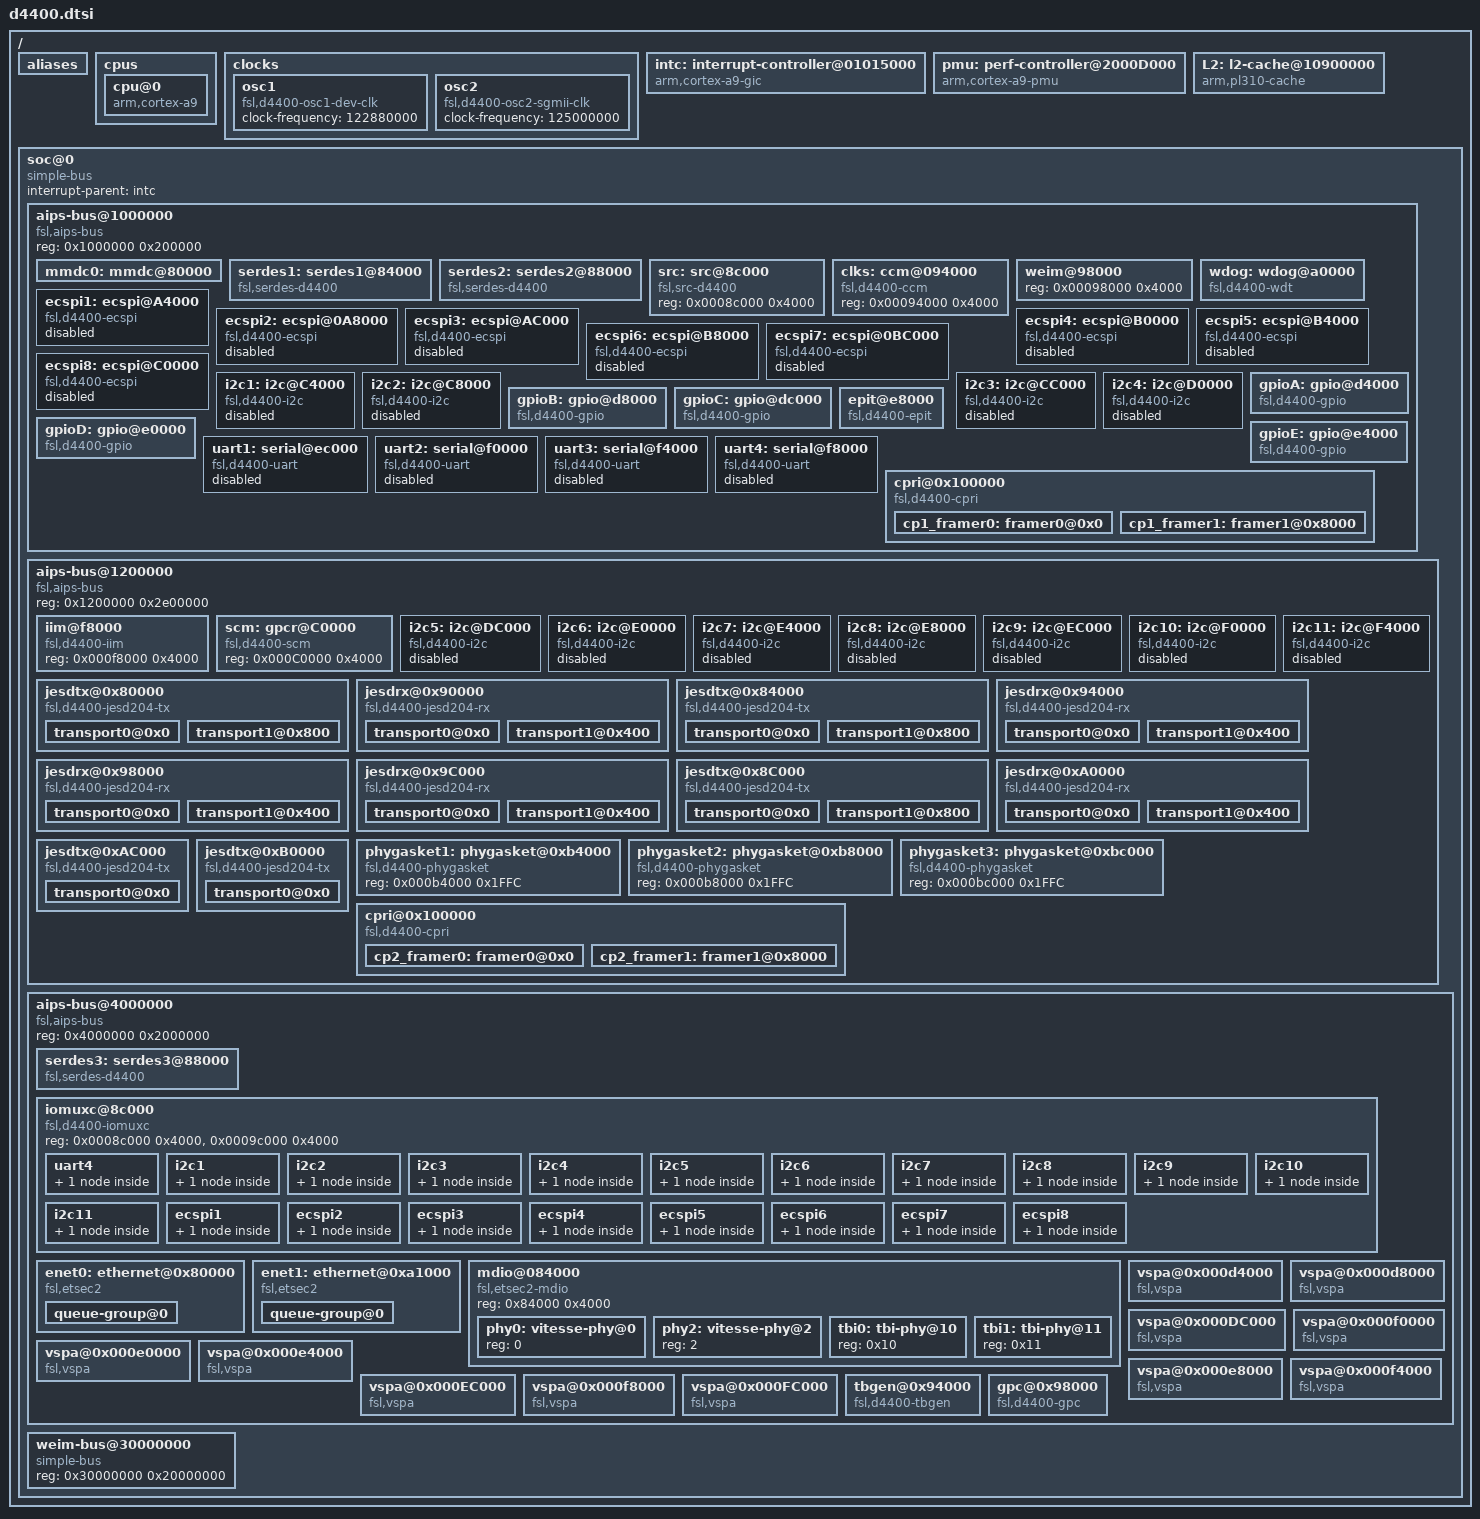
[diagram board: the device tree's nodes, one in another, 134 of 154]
/*
 * Copyright 2013 Freescale Semiconductor, Inc.
 * Copyright 2011 Linaro Ltd.
 *
 * The code contained herein is licensed under the GNU General Public
 * License. You may obtain a copy of the GNU General Public License
 * Version 2 or later at the following locations:
 *
 * http://www.opensource.org/licenses/gpl-license.html
 * http://www.gnu.org/copyleft/gpl.html
 */

/include/ "skeleton.dtsi"

/ {
        aliases {
                serial0 = &uart1;
                serial1 = &uart2;
                serial2 = &uart3;
                serial3 = &uart4;
                gpio0 = &gpioA;
                gpio1 = &gpioB;
                gpio2 = &gpioC;
                gpio3 = &gpioD;
                gpio4 = &gpioE;
		ethernet0 = &enet0;
		ethernet1 = &enet1;
		cpri0ethernet0 = &cp1_framer0;
		cpri0ethernet1 = &cp1_framer1;
		cpri1ethernet0 = &cp2_framer0;
		cpri1ethernet1 = &cp2_framer1;
        };

        cpus {
                #address-cells = <1>;
                #size-cells = <0>;

                cpu@0 {
                        compatible = "arm,cortex-a9";
                        reg = <0>;
                        next-level-cache = <&L2>;
                };
        };

        clocks {
                #address-cells = <1>;
                #size-cells = <0>;
                osc1 {
                        compatible = "fsl,d4400-osc1-dev-clk", "fixed-clock";
                        clock-frequency = <122880000>;
                };

                osc2 {
                        compatible = "fsl,d4400-osc2-sgmii-clk", "fixed-clock";
                        clock-frequency = <125000000>;
                };


        };

        intc: interrupt-controller@01015000 {
                compatible = "arm,cortex-a9-gic";
                #interrupt-cells = <3>;
                #address-cells = <1>;
                #size-cells = <1>;
                interrupt-controller;
                reg = <0x01015000 0x1000>, /* distributor address */
                      <0x01014100 0x100>;  /* CPU interface address */
        };

        pmu: perf-controller@2000D000 {
                compatible = "arm,cortex-a9-pmu";
                interrupts = <0 60 0x04>;
                reg = <0x2000D000 0x1000>;
        };

        L2: l2-cache@10900000 {
                compatible = "arm,pl310-cache";
                reg = <0x10900000 0x4000>;
                interrupts = <0 59 0x04>;
                cache-unified;
                cache-level = <2>;
        };

        soc@0 {
                #address-cells = <1>;
                #size-cells = <1>;
                compatible = "simple-bus";
                interrupt-parent = <&intc>;
                ranges = <0x0 0x0 0xFFFFFFFF>;

                aips-bus@1000000 { /* AIPS1 */
                        compatible = "fsl,aips-bus", "simple-bus";
                        #address-cells = <1>;
                        #size-cells = <1>;
                        reg = <0x1000000 0x200000>;
                        ranges = <0x0 0x1000000 0x200000>;

                        mmdc0: mmdc@80000 { /* MMDC0 */
                                reg = <0x00080000 0x4000>;
                                interrupts = <0 45 0x04>;
                        };

			serdes1: serdes1@84000 {
				#address-cells = <1>;
				#size-cells = <1>;
				#serdes-cells = <1>;
				compatible = "fsl,serdes-d4400";
				serdes-id = <1>;
				max-lane = <8>;
				reg = <0x00084000 0x4000>;
			};

			serdes2: serdes2@88000 {
				#address-cells = <1>;
				#size-cells = <1>;
				#serdes-cells = <1>;
				compatible = "fsl,serdes-d4400";
				serdes-id = <2>;
				max-lane = <8>;
				reg = <0x00088000 0x4000>;
			};

			src: src@8c000 {
				#address-cells = <1>;
				#size-cells = <1>;
				#src-cells = <1>;
				compatible = "fsl,src-d4400";
				reg = <0x0008c000 0x4000>;
			};

                        clks: ccm@094000 {
                                compatible = "fsl,d4400-ccm";
                                reg = <0x00094000 0x4000>;
                                #clock-cells = <1>;
                        };

                        weim@98000 {
                                reg = <0x00098000 0x4000>;
                        };

			wdog: wdog@a0000 {
				reg = <0x000a0000 0x4000>;
                                compatible = "fsl,d4400-wdt";
				interrupts = <0 47 0x04>;
				clocks = <&clks 31>;
			};

			ecspi1: ecspi@A4000 {
				#address-cells = <1>;
				#size-cells = <0>;
				compatible = "fsl,d4400-ecspi";
				reg = <0x000A4000 0x4000>;
				interrupts = <0 13 0x04>;
				clocks = <&clks 32>, <&clks 33>;
				clock-names = "ipg", "per";
				status = "disabled";
			};

			ecspi2: ecspi@0A8000 {
				#address-cells = <1>;
				#size-cells = <0>;
				compatible = "fsl,d4400-ecspi";
				reg = <0x000A8000 0x4000>;
				interrupts = <0 14 0x04>;
				clocks = <&clks 34>, <&clks 35>;
				clock-names = "ipg", "per";
				status = "disabled";
			};

			ecspi3: ecspi@AC000 {
				#address-cells = <1>;
				#size-cells = <0>;
				compatible = "fsl,d4400-ecspi";
				reg = <0x000AC000 0x4000>;
				interrupts = <0 15 0x04>;
				clocks = <&clks 36>, <&clks 37>;
				clock-names = "ipg", "per";
				status = "disabled";
			};

			ecspi4: ecspi@B0000 {
				#address-cells = <1>;
				#size-cells = <0>;
				compatible = "fsl,d4400-ecspi";
				reg = <0x000B0000 0x4000>;
				interrupts = <0 16 0x04>;
				clocks = <&clks 38>, <&clks 39>;
				clock-names = "ipg", "per";
				status = "disabled";
			};

			ecspi5: ecspi@B4000 {
				#address-cells = <1>;
				#size-cells = <0>;
				compatible = "fsl,d4400-ecspi";
				reg = <0x000B4000 0x4000>;
				interrupts = <0 17 0x04>;
				clocks = <&clks 40>, <&clks 41>;
				clock-names = "ipg", "per";
				status = "disabled";
			};

			ecspi6: ecspi@B8000 {
				#address-cells = <1>;
				#size-cells = <0>;
				compatible = "fsl,d4400-ecspi";
				reg = <0x000B8000 0x4000>;
				interrupts = <0 18 0x04>;
				clocks = <&clks 42>, <&clks 43>;
				clock-names = "ipg", "per";
				status = "disabled";
			};

			ecspi7: ecspi@0BC000 {
				#address-cells = <1>;
				#size-cells = <0>;
				compatible = "fsl,d4400-ecspi";
				reg = <0x000BC000 0x4000>;
				interrupts = <0 19 0x04>;
				clocks = <&clks 44>, <&clks 45>;
				clock-names = "ipg", "per";
				status = "disabled";
			};

			ecspi8: ecspi@C0000 {
				#address-cells = <1>;
				#size-cells = <0>;
				compatible = "fsl,d4400-ecspi";
				reg = <0x000C0000 0x4000>;
				interrupts = <0 20 0x04>;
				clocks = <&clks 46>, <&clks 47>;
				clock-names = "ipg", "per";
				status = "disabled";
			};

			i2c1: i2c@C4000 {
				#address-cells = <1>;
				#size-cells = <0>;
				compatible = "fsl,d4400-i2c";
				reg = <0x000C4000 0x4000>;
				interrupts = <0 48 0x04>;
				clocks = <&clks 65>;
				status = "disabled";
			};

			i2c2: i2c@C8000 {
				#address-cells = <1>;
				#size-cells = <0>;
				compatible = "fsl,d4400-i2c";
				reg = <0x000C8000 0x4000>;
				interrupts = <0 49 0x04>;
				clocks = <&clks 66>;
				status = "disabled";
			};

			i2c3: i2c@CC000 {
				#address-cells = <1>;
				#size-cells = <0>;
				compatible = "fsl,d4400-i2c";
				reg = <0x000CC000 0x4000>;
				interrupts = <0 50 0x04>;
				clocks = <&clks 67>;
				status = "disabled";
			};

			i2c4: i2c@D0000 {
				#address-cells = <1>;
				#size-cells = <0>;
				compatible = "fsl,d4400-i2c";
				reg = <0x000D0000 0x4000>;
				interrupts = <0 51 0x04>;
				clocks = <&clks 68>;
				status = "disabled";
			};

                        gpioA: gpio@d4000 {
                                compatible = "fsl,d4400-gpio";
                                reg = <0x000d4000 0x4000>;
                                interrupts = <0 159 0x04>;
                                gpio-controller;
                                #gpio-cells = <2>;
                                interrupt-controller;
                                #interrupt-cells = <2>;
                        };

                        gpioB: gpio@d8000 {
                                compatible = "fsl,d4400-gpio";
                                reg = <0x000d8000 0x4000>;
                                interrupts = <0 160 0x04>;
                                gpio-controller;
                                #gpio-cells = <2>;
                                interrupt-controller;
                                #interrupt-cells = <2>;
                        };

                        gpioC: gpio@dc000 {
                                compatible = "fsl,d4400-gpio";
                                reg = <0x000dc000 0x4000>;
                                interrupts = <0 161 0x04>;
                                gpio-controller;
                                #gpio-cells = <2>;
                                interrupt-controller;
                                #interrupt-cells = <2>;
                        };

                        gpioD: gpio@e0000 {
                                compatible = "fsl,d4400-gpio";
                                reg = <0x000e0000 0x4000>;
                                interrupts = <0 162 0x04>;
                                gpio-controller;
                                #gpio-cells = <2>;
                                interrupt-controller;
                                #interrupt-cells = <2>;
                        };

                        gpioE: gpio@e4000 {
                                compatible = "fsl,d4400-gpio";
                                reg = <0x000e4000 0x4000>;
                                interrupts = <0 163 0x04>;
                                gpio-controller;
                                #gpio-cells = <2>;
                                interrupt-controller;
                                #interrupt-cells = <2>;
                        };

                        epit@e8000 {
				compatible = "fsl,d4400-epit";
                                reg = <0x000e8000 0x4000>;
                                interrupts = <0 22 0x04>;
                        };

                        uart1: serial@ec000 {
                                 compatible = "fsl,d4400-uart";
                                 reg = <0x000ec000 0x4000>;
                                 interrupts = <0 0 0x04>;
                                 clocks = <&clks 57>, <&clks 18>;
                                 clock-names = "ipg", "per";
                                 status = "disabled";
                        };

                        uart2: serial@f0000 {
                                 compatible = "fsl,d4400-uart";
                                 reg = <0x000f0000 0x4000>;
                                 interrupts = <0 1 0x04>;
                                 clocks = <&clks 59>, <&clks 20>;
                                 clock-names = "ipg", "per";
                                 status = "disabled";
                        };

                        uart3: serial@f4000 {
                                 compatible = "fsl,d4400-uart";
                                 reg = <0x000f4000 0x4000>;
                                 interrupts = <0 2 0x04>;
                                 clocks = <&clks 61>, <&clks 22>;
                                 clock-names = "ipg", "per";
                                 status = "disabled";
                        };

                        uart4: serial@f8000 {
                                 compatible = "fsl,d4400-uart";
                                 reg = <0x000f8000 0x4000>;
                                 interrupts = <0 3 0x04>;
                                 clocks = <&clks 63>, <&clks 24>;
                                 clock-names = "ipg", "per";
                                 status = "disabled";
                        };
			cpri@0x100000 {
				#address-cells = <1>;
				#size-cells = <1>;
				compatible = "fsl,d4400-cpri";
				id = <1>;
				ranges = <0x0 0x100000 0x10000>;
				reg = <0x00107E00 0x400>;
				status = "okay";
				interrupts = <0 67 0x4>,
					<0 68 0x4>,
					<0 69 0x4>,
					<0 70 0x4>,
					<0 79 0x4>;

			cp1_framer0: framer0@0x0 {
				reg = <0x0 0x8000>;
				framer-id = <1>;
				max-axcs = <24>;
				memblk-rx = <0x83000000 0x1800 0x83801800 0x1800>;
				memblk-tx = <0x83000000 0x1800 0x83801800 0x1800>;
				local-mac-address = [ 00 00 AB CD 21 AB ];
				interrupts = <0 71 0x04>,
					 <0 73 0x04>,
					 <0 75 0x04>,
					 <0 77 0x04>;
				sfp-handle = <&cpriphy0>;
				serdes-handle = <&serdes3 2>;
			};

			cp1_framer1: framer1@0x8000 {
				reg = <0x8000 0x8000>;
				framer-id = <2>;
				max-axcs = <24>;
				memblk-rx = <0x84000000 0x1800 0x84801800 0x1800>;
				memblk-tx = <0x84000000 0x1800 0x84801800 0x1800>;
				local-mac-address = [ 00 00 AB CD 21 CD ];
				interrupts = <0 72 0x4>,
					 <0 74 0x4>,
					 <0 76 0x4>,
					 <0 78 0x4>;
				sfp-handle = <&cpriphy1>;
				serdes-handle = <&serdes3 3>;
				};
			};



                };

                aips-bus@1200000 { /* AIPS2 */
                        compatible = "fsl,aips-bus", "simple-bus";
                        #address-cells = <1>;
                        #size-cells = <1>;
                        reg = <0x1200000 0x2e00000>;
                        ranges = <0x0 0x1200000 0x2e00000>;
			iim@f8000 {
				compatible = "fsl,d4400-iim";
				reg = <0x000f8000 0x4000>;
			};
			scm: gpcr@C0000 {
                                 compatible = "fsl,d4400-scm";
                                 reg = <0x000C0000 0x4000>;
			};

			i2c5: i2c@DC000 {
				#address-cells = <1>;
				#size-cells = <0>;
				compatible = "fsl,d4400-i2c";
				reg = <0x000DC000 0x4000>;
				interrupts = <0 52 0x04>;
				clocks = <&clks 69>;
				status = "disabled";
			};

			i2c6: i2c@E0000 {
				#address-cells = <1>;
				#size-cells = <0>;
				compatible = "fsl,d4400-i2c";
				reg = <0x000E0000 0x4000>;
				interrupts = <0 53 0x04>;
				clocks = <&clks 70>;
				status = "disabled";
			};

			i2c7: i2c@E4000 {
				#address-cells = <1>;
				#size-cells = <0>;
				compatible = "fsl,d4400-i2c";
				reg = <0x000E4000 0x4000>;
				interrupts = <0 54 0x04>;
				clocks = <&clks 71>;
				status = "disabled";
			};

			i2c8: i2c@E8000 {
				#address-cells = <1>;
				#size-cells = <0>;
				compatible = "fsl,d4400-i2c";
				reg = <0x000E8000 0x4000>;
				interrupts = <0 55 0x04>;
				clocks = <&clks 72>;
				status = "disabled";
			};

			i2c9: i2c@EC000 {
				#address-cells = <1>;
				#size-cells = <0>;
				compatible = "fsl,d4400-i2c";
				reg = <0x000EC000 0x4000>;
				interrupts = <0 56 0x04>;
				clocks = <&clks 73>;
				status = "disabled";
			};

			i2c10: i2c@F0000 {
				#address-cells = <1>;
				#size-cells = <0>;
				compatible = "fsl,d4400-i2c";
				reg = <0x000F0000 0x4000>;
				interrupts = <0 57 0x04>;
				clocks = <&clks 74>;
				status = "disabled";
			};

			i2c11: i2c@F4000 {
				#address-cells = <1>;
				#size-cells = <0>;
				compatible = "fsl,d4400-i2c";
				reg = <0x000F4000 0x4000>;
				interrupts = <0 58 0x04>;
				clocks = <&clks 75>;
				status = "disabled";
			};

			jesdtx@0x80000{
				#address-cells = <1>;
				#size-cells = <1>;
				compatible = "fsl,d4400-jesd204-tx";
				ranges = <0x0 0x80000 0x4000>;
				reg = <0x00080000 0x4000>;
				lanes = <2>;

				transport0@0x0{
					reg = <0x0000000 0x7FC>;
					transport-type = <0>;
					transport-id = <0>;
					timer-id = <0>;
					pll-id = <0>;
					phy-gasket = <&phygasket1>;
					max-lanes = <2>;
					serdes-lanes = <&serdes1 0>,
						<&serdes1 1>;
					interrupts = <0 119 0x4>;
				};

				transport1@0x800{
					reg = <0x00000800 0x7FC>;
					transport-type = <0>;
					transport-id = <1>;
					timer-id = <1>;
					pll-id = <0>;
					phy-gasket = <&phygasket1>;
					max-lanes = <1>;
					serdes-lanes = <&serdes1 1>;
					interrupts = <0 120 0x4>;
				};
			};

			jesdrx@0x90000{
				#address-cells = <1>;
				#size-cells = <1>;
				compatible = "fsl,d4400-jesd204-rx";
				ranges = <0x0 0x90000 0x4000>;
				reg = <0x00090000 0x4000>;
				lanes = <2>;

				transport0@0x0{
					reg = <0x00000000 0x3FF>;
					transport-type = <2>;
					transport-id = <0>;
					timer-id = <0>;
					pll-id = <0>;
					phy-gasket = <&phygasket1>;
					max-lanes = <2>;
					serdes-lanes = <&serdes1 0>,
						<&serdes1 1>;
					interrupts = <0 106 0x4>;
				};

				transport1@0x400{
					reg = <0x00000400 0x3FF>;
					transport-type = <2>;
					transport-id = <1>;
					timer-id = <1>;
					pll-id = <0>;
					phy-gasket = <&phygasket1>;
					max-lanes = <1>;
					serdes-lanes = <&serdes1 1>;
					interrupts = <0 107 0x4>;
				};
			};

			jesdtx@0x84000{
				#address-cells = <1>;
				#size-cells = <1>;
				compatible = "fsl,d4400-jesd204-tx";
				ranges = <0x0 0x84000 0x4000>;
				reg = <0x00084000 0x4000>;
				lanes = <2>;

				transport0@0x0{
					reg = <0x0000000 0x7FC>;
					transport-type = <0>;
					transport-id = <2>;
					timer-id = <2>;
					pll-id = <0>;
					phy-gasket = <&phygasket1>;
					max-lanes = <2>;
					serdes-lanes = <&serdes1 2>,
						<&serdes1 3>;
					interrupts = <0 121 0x4>;
				};

				transport1@0x800{
					reg = <0x00000800 0x7FC>;
					transport-type = <0>;
					transport-id = <3>;
					timer-id = <3>;
					pll-id = <0>;
					phy-gasket = <&phygasket1>;
					max-lanes = <1>;
					serdes-lanes = <&serdes1 3>;
					interrupts = <0 122 0x4>;
				};
			};

			jesdrx@0x94000{
				#address-cells = <1>;
				#size-cells = <1>;
				compatible = "fsl,d4400-jesd204-rx";
				ranges = <0x0 0x94000 0x4000>;
				reg = <0x00094000 0x4000>;
				lanes = <2>;

				transport0@0x0{
					reg = <0x00000000 0x3FF>;
					transport-type = <1>;
					transport-id = <2>;
					timer-id = <0>;
					pll-id = <0>;
					phy-gasket = <&phygasket1>;
					max-lanes = <2>;
					serdes-lanes = <&serdes1 2>,
						<&serdes1 3>;
					interrupts = <0 108 0x4>;
				};

				transport1@0x400{
					reg = <0x00000400 0x3FF>;
					transport-type = <1>;
					transport-id = <3>;
					timer-id = <1>;
					pll-id = <0>;
					phy-gasket = <&phygasket1>;
					max-lanes = <1>;
					serdes-lanes = <&serdes1 3>;
					interrupts = <0 109 0x4>;
				};
			};

			jesdrx@0x98000{
				#address-cells = <1>;
				#size-cells = <1>;
				compatible = "fsl,d4400-jesd204-rx";
				ranges = <0x0 0x98000 0x4000>;
				reg = <0x00098000 0x4000>;
				lanes = <2>;

				transport0@0x0{
					reg = <0x00000000 0x3FF>;
					transport-type = <2>;
					transport-id = <4>;
					timer-id = <2>;
					pll-id = <0>;
					phy-gasket = <&phygasket1>;
					max-lanes = <2>;
					serdes-lanes = <&serdes1 4>,
						<&serdes1 5>;
					interrupts = <0 110 0x4>;
				};

				transport1@0x400{
					reg = <0x00000400 0x3FF>;
					transport-type = <2>;
					transport-id = <5>;
					timer-id = <3>;
					pll-id = <0>;
					phy-gasket = <&phygasket1>;
					max-lanes = <1>;
					serdes-lanes = <&serdes1 5>;
					interrupts = <0 111 0x4>;
				};
			};

			jesdrx@0x9C000{
				#address-cells = <1>;
				#size-cells = <1>;
				compatible = "fsl,d4400-jesd204-rx";
				ranges = <0x0 0x9C000 0x4000>;
				reg = <0x0009C000 0x4000>;
				lanes = <2>;

				transport0@0x0{
					reg = <0x00000000 0x3FF>;
					transport-type = <1>;
					transport-id = <6>;
					timer-id = <2>;
					pll-id = <0>;
					phy-gasket = <&phygasket1>;
					max-lanes = <2>;
					serdes-lanes = <&serdes1 6>,
						<&serdes1 7>;
					interrupts = <0 112 0x4>;
				};

				transport1@0x400{
					reg = <0x00000400 0x3FF>;
					transport-type = <1>;
					transport-id = <7>;
					timer-id = <3>;
					pll-id = <0>;
					phy-gasket = <&phygasket1>;
					max-lanes = <1>;
					serdes-lanes = <&serdes1 7>;
					interrupts = <0 113 0x4>;
				};
			};

			jesdtx@0x8C000{
				#address-cells = <1>;
				#size-cells = <1>;
				compatible = "fsl,d4400-jesd204-tx";
				ranges = <0x0 0x8C000 0x4000>;
				reg = <0x0008C000 0x4000>;
				lanes = <2>;

				transport0@0x0{
					reg = <0x0000000 0x7FC>;
					transport-type = <0>;
					transport-id = <6>;
					timer-id = <6>;
					pll-id = <0>;
					phy-gasket = <&phygasket1>;
					max-lanes = <2>;
					serdes-lanes = <&serdes1 6>,
						<&serdes1 7>;
					interrupts = <0 125 0x4>;
				};

				transport1@0x800{
					reg = <0x00000800 0x7FC>;
					transport-type = <0>;
					transport-id = <7>;
					timer-id = <7>;
					pll-id = <0>;
					phy-gasket = <&phygasket1>;
					max-lanes = <1>;
					serdes-lanes = <&serdes1 7>;
					interrupts = <0 126 0x4>;
				};
			};

			jesdrx@0xA0000{
				#address-cells = <1>;
				#size-cells = <1>;
				compatible = "fsl,d4400-jesd204-rx";
				ranges = <0x0 0xA0000 0x4000>;
				reg = <0x000A0000 0x4000>;
				lanes = <2>;

				transport0@0x0{
					reg = <0x00000000 0x3FF>;
					transport-type = <1>;
					transport-id = <8>;
					timer-id = <8>;
					pll-id = <1>;
					phy-gasket = <&phygasket2>;
					max-lanes = <2>;
					serdes-lanes = <&serdes2 2>,
						<&serdes2 3>;
					interrupts = <0 114 0x4>;
				};

				transport1@0x400{
					reg = <0x00000400 0x3FF>;
					transport-type = <1>;
					transport-id = <9>;
					timer-id = <9>;
					pll-id = <1>;
					phy-gasket = <&phygasket2>;
					max-lanes = <1>;
					serdes-lanes = <&serdes2 3>;
					interrupts = <0 115 0x4>;
				};
			};

			jesdtx@0xAC000{
				#address-cells = <1>;
				#size-cells = <1>;
				compatible = "fsl,d4400-jesd204-tx";
				ranges = <0x0 0xAC000 0x4000>;
				reg = <0x000AC000 0x4000>;
				lanes = <2>;

				transport0@0x0{
					reg = <0x0000000 0x7FC>;
					transport-type = <0>;
					transport-id = <8>;
					timer-id = <8>;
					pll-id = <2>;
					phy-gasket = <&phygasket3>;
					max-lanes = <2>;
					serdes-lanes = <&serdes3 4>,
						<&serdes3 5>;
					interrupts = <0 127 0x4>;
				};
			};

			jesdtx@0xB0000{
				#address-cells = <1>;
				#size-cells = <1>;
				compatible = "fsl,d4400-jesd204-tx";
				ranges = <0x0 0xB0000 0x4000>;
				reg = <0x000B0000 0x4000>;
				lanes = <2>;

				transport0@0x0{
					reg = <0x0000000 0x7FC>;
					transport-type = <0>;
					transport-id = <9>;
					timer-id = <9>;
					pll-id = <2>;
					phy-gasket = <&phygasket3>;
					max-lanes = <2>;
					serdes-lanes = <&serdes3 6>,
						<&serdes3 7>;
					interrupts = <0 128 0x4>;
				};
			};

			phygasket1: phygasket@0xb4000 {
				#address-cells = <1>;
				#size-cells = <1>;
				compatible = "fsl,d4400-phygasket";
				reg = <0x000b4000 0x1FFC>;
			};

			phygasket2: phygasket@0xb8000 {
				#address-cells = <1>;
				#size-cells = <1>;
				compatible = "fsl,d4400-phygasket";
				reg = <0x000b8000 0x1FFC>;
			};

			phygasket3: phygasket@0xbc000 {
				#address-cells = <1>;
				#size-cells = <1>;
				compatible = "fsl,d4400-phygasket";
				reg = <0x000bc000 0x1FFC>;
			};

			cpri@0x100000 {
                                #address-cells = <1>;
                                #size-cells = <1>;
                                compatible = "fsl,d4400-cpri";
                                id = <2>;
                                ranges = <0x0 0x100000 0x10000>;
                                reg = <0x00107E00 0x400>;
                                status = "okay";
                                interrupts = <0 80 0x4>,
                                        <0 81 0x4>,
                                        <0 82 0x4>,
                                        <0 83 0x4>,
                                        <0 92 0x4>;

                        cp2_framer0: framer0@0x0 {
                                reg = <0x0 0x8000>;
                                framer-id = <1>;
                                max-axcs = <24>;
                                memblk-rx = <0x85000000 0x1800 0x85801800 0x1800>;
                                memblk-tx = <0x85000000 0x1800 0x85801800 0x1800>;
                                local-mac-address = [ 00 00 AB CD 21 EF ];
                                interrupts = <0 84 0x04>,
                                         <0 86 0x04>,
                                         <0 88 0x04>,
                                         <0 90 0x04>;
                                sfp-handle = <&cpriphy2>;
                                serdes-handle = <&serdes3 4>;
                        };

                        cp2_framer1: framer1@0x8000 {
                                reg = <0x8000 0x8000>;
                                framer-id = <2>;
                                max-axcs = <24>;
                                memblk-rx = <0x86000000 0x1800 0x86801800 0x1800>;
                                memblk-tx = <0x86000000 0x1800 0x86801800 0x1800>;
                                local-mac-address = [ 00 00 AB CD 22 AB ];
                                interrupts = <0 85 0x4>,
                                         <0 87 0x4>,
                                         <0 89 0x4>,
                                         <0 91 0x4>;
                                sfp-handle = <&cpriphy3>;
                                serdes-handle = <&serdes3 5>;
                                };
                        };


                };

                aips-bus@4000000 { /* AIPS3 */
                        compatible = "fsl,aips-bus", "simple-bus";
                        #address-cells = <1>;
                        #size-cells = <1>;
                        reg = <0x4000000 0x2000000>;
                        ranges = <0x0 0x4000000 0x2000000>;

			serdes3: serdes3@88000 {
				#address-cells = <1>;
				#size-cells = <1>;
				#serdes-cells = <1>;
				compatible = "fsl,serdes-d4400";
				serdes-id = <3>;
				max-lane = <8>;
				reg = <0x00088000 0x4000>;
			};

                        iomuxc@8c000 {
                                compatible = "fsl,d4400-iomuxc";
                                reg = <0x0008c000 0x4000>, < 0x0009c000 0x4000>;
				reg-names = "iomuxc-ddr", "iomuxc-main";
                                uart4 {
                                        pinctrl_uart4_1: uart4grp-1 {
                                                fsl,pins = <
                                                        350 0x80000000    /* D4400_PAD_UART4_TXD_UART_4_TXD */
                                                        356 0x80000000    /* D4400_PAD_UART4_RXD_UART_4_RXD */
                                                >;
                                        };
                                };

				i2c1 {
					pinctrl_i2c1_1: i2c1grp-1 {
						fsl,pins = <
							362 0x80000000	/* D4400_PAD_I2C1_SDA_I2C_1_SDA */
							367 0x80000000	/* D4400_PAD_I2C1_SCL_I2C_1_SCL */
						>;
					};
				};

				i2c2 {
					pinctrl_i2c2_1: i2c2grp-1 {
						fsl,pins = <
							372 0x80000000	/* D4400_PAD_I2C2_SDA_I2C_2_SDA */
							377 0x80000000	/* D4400_PAD_I2C2_SCL_I2C_2_SCL */
						>;
					};
				};

				i2c3 {
					pinctrl_i2c3_1: i2c3grp-1 {
						fsl,pins = <
							382 0x80000000	/* D4400_PAD_I2C3_SDA_I2C_3_SDA */
							387 0x80000000	/* D4400_PAD_I2C3_SCL_I2C_3_SCL */
						>;
					};
				};

				i2c4 {
					pinctrl_i2c4_1: i2c4grp-1 {
						fsl,pins = <
							352 0x80000000	/* D4400_PAD_UART4_TXD_I2C_4_SDA */
							358 0x80000000	/* D4400_PAD_UART4_RXD_I2C_4_SCL */
						>;
					};
				};

				i2c5 {
					pinctrl_i2c5_1: i2c5grp-1 {
						fsl,pins = <
							392 0x80000000	/* D4400_PAD_I2C5_SDA_I2C_5_SDA */
							397 0x80000000	/* D4400_PAD_I2C5_SCL_I2C_5_SCL */
						>;
					};
				};

				i2c6 {
					pinctrl_i2c6_1: i2c6grp-1 {
						fsl,pins = <
							402 0x80000000	/* D4400_PAD_I2C6_SDA_I2C_6_SDA */
							407 0x80000000	/* D4400_PAD_I2C6_SCL_I2C_6_SCL */
						>;
					};
				};

				i2c7 {
					pinctrl_i2c7_1: i2c7grp-1 {
						fsl,pins = <
							412 0x80000000	/* D4400_PAD_I2C7_SDA_I2C_7_SDA */
							417 0x80000000	/* D4400_PAD_I2C7_SCL_I2C_7_SCL */
						>;
					};
				};

				i2c8 {
					pinctrl_i2c8_1: i2c8grp-1 {
						fsl,pins = <
							422 0x80000000	/* D4400_PAD_I2C8_SDA_I2C_8_SDA */
							430 0x80000000	/* D4400_PAD_I2C8_SCL_I2C_8_SCL */
						>;
					};
				};

				i2c9 {
					pinctrl_i2c9_1: i2c9grp-1 {
						fsl,pins = <
							438 0x80000000	/* D4400_PAD_I2C9_SDA_I2C_9_SDA */
							446 0x80000000	/* D4400_PAD_I2C9_SCL_I2C_9_SCL */
						>;
					};
				};

				i2c10 {
					pinctrl_i2c10_1: i2c10grp-1 {
						fsl,pins = <
							454 0x80000000	/* D4400_PAD_I2C10_SDA_I2C_10_SDA */
							462 0x80000000	/* D4400_PAD_I2C10_SCL_I2C_10_SCL */
						>;
					};
				};

				i2c11 {
					pinctrl_i2c11_1: i2c11grp-1 {
						fsl,pins = <
							470 0x80000000	/* D4400_PAD_I2C11_SDA_I2C_11_SDA */
							478 0x80000000	/* D4400_PAD_I2C11_SCL_I2C_11_SCL */
						>;
					};
				};

				ecspi1 {
					pinctrl_ecspi1_1: ecspi1grp-1 {
						fsl,pins = <
							182 0x80000000	/* D4400_PAD_SPI1_MOSI_ECSPI_1_MOSI */
							186 0x80000000	/* D4400_PAD_SPI1_MISO_ECSPI_1_MISO */
							189 0x80000000	/* D4400_PAD_SPI1_CLK_ECSPI_1_CLK */
							192 0x80000000	/* D4400_PAD_SPI1_SS0_ECSPI_1_SS_0 */
							195 0x80000000	/* D4400_PAD_SPI1_SS1_ECSPI_1_SS_1 */
							841 0x80000000  /* D4400_PAD_GPIOC0_ECSPI1_SS2 */
						>;
					};
				};

				ecspi2 {
					pinctrl_ecspi2_1: ecspi2grp-1 {
						fsl,pins = <
							198 0x80000000	/* D4400_PAD_SPI2_MOSI_ECSPI_2_MOSI */
							202 0x80000000	/* D4400_PAD_SPI2_MISO_ECSPI_2_MISO */
							205 0x80000000	/* D4400_PAD_SPI2_CLK_ECSPI_2_CLK */
							208 0x80000000	/* D4400_PAD_SPI2_SS0_ECSPI_2_SS_0 */
							211 0x80000000	/* D4400_PAD_SPI2_SS1_ECSPI_2_SS_1 */
						>;
					};
				};

				ecspi3 {
					pinctrl_ecspi3_1: ecspi3grp-1 {
						fsl,pins = <
							214 0x80000000	/* D4400_PAD_SPI3_MOSI_ECSPI_3_MOSI */
							218 0x80000000	/* D4400_PAD_SPI3_MISO_ECSPI_3_MISO */
							221 0x80000000	/* D4400_PAD_SPI3_CLK_ECSPI_3_CLK */
							224 0x80000000	/* D4400_PAD_SPI3_SS0_ECSPI_3_SS_0 */
							227 0x80000000	/* D4400_PAD_SPI3_SS1_ECSPI_3_SS_1 */
							873 0x80000000  /* D4400_PAD_GPIOC4_ECSPI3_SS2 */
						>;
					};
				};

				ecspi4 {
					pinctrl_ecspi4_1: ecspi4grp-1 {
						fsl,pins = <
							230 0x80000000	/* D4400_PAD_SPI4_MOSI_ECSPI_4_MOSI */
							234 0x80000000	/* D4400_PAD_SPI4_MISO_ECSPI_4_MISO */
							237 0x80000000	/* D4400_PAD_SPI4_CLK_ECSPI_4_CLK */
							240 0x80000000	/* D4400_PAD_SPI4_SS0_ECSPI_4_SS_0 */
							243 0x80000000	/* D4400_PAD_SPI4_SS1_ECSPI_4_SS_1 */
						>;
					};
				};

				ecspi5 {
					pinctrl_ecspi5_1: ecspi5grp-1 {
						fsl,pins = <
							246 0x80000000	/* D4400_PAD_SPI5_MOSI_ECSPI_5_MOSI */
							250 0x80000000	/* D4400_PAD_SPI5_MISO_ECSPI_5_MISO */
							253 0x80000000	/* D4400_PAD_SPI5_CLK_ECSPI_5_CLK */
							256 0x80000000	/* D4400_PAD_SPI5_SS0_ECSPI_5_SS_0 */
							259 0x80000000	/* D4400_PAD_SPI5_SS1_ECSPI_5_SS_1 */
						>;
					};
				};

				ecspi6 {
					pinctrl_ecspi6_1: ecspi6grp-1 {
						fsl,pins = <
							262 0x80000000	/* D4400_PAD_SPI6_MOSI_ECSPI_6_MOSI */
							267 0x80000000	/* D4400_PAD_SPI6_MISO_ECSPI_6_MISO */
							271 0x80000000	/* D4400_PAD_SPI6_CLK_ECSPI_6_CLK */
							275 0x80000000	/* D4400_PAD_SPI6_SS0_ECSPI_6_SS_0 */
							279 0x80000000	/* D4400_PAD_SPI6_SS1_ECSPI_6_SS_1 */
						>;
					};
				};

				ecspi7 {
					pinctrl_ecspi7_1: ecspi7grp-1 {
						fsl,pins = <
							282 0x80000000	/* D4400_PAD_SPI7_MOSI_ECSPI_7_MOSI */
							287 0x80000000	/* D4400_PAD_SPI7_MISO_ECSPI_7_MISO */
							291 0x80000000	/* D4400_PAD_SPI7_CLK_ECSPI_7_CLK */
							295 0x80000000	/* D4400_PAD_SPI7_SS0_ECSPI_7_SS_0 */
							299 0x80000000	/* D4400_PAD_SPI7_SS1_ECSPI_7_SS_1 */
						>;
					};
				};

				ecspi8 {
					pinctrl_ecspi8_1: ecspi8grp-1 {
						fsl,pins = <
							302 0x80000000	/* D4400_PAD_SPI8_MOSI_ECSPI_8_MOSI */
							307 0x80000000	/* D4400_PAD_SPI8_MISO_ECSPI_8_MISO */
							311 0x80000000	/* D4400_PAD_SPI8_CLK_ECSPI_8_CLK */
							316 0x80000000	/* D4400_PAD_SPI8_SS0_ECSPI_8_SS_0 */
							321 0x80000000	/* D4400_PAD_SPI8_SS1_ECSPI_8_SS_1 */
						>;
					};
				};

                        };

			enet0: ethernet@0x80000 {
				#address-cells = <1>;
				#size-cells = <1>;
				device_type = "network";
				model = "eTSEC";
				compatible = "fsl,etsec2";
				fsl,num_rx_queues = <0x08>;
				fsl,num_tx_queues = <0x08>;
				fsl,errata = <0x00000004>;
				local-mac-address = [ 00 00 ab cd 22 ef ];
				phy-handle = <&phy0>;
				tbi-handle = <&tbi0>;
				phy-connection-type = "sgmii";
				reg = <0x80000 0x1000>;
				ranges;
				status = "okay";

				queue-group@0 {
					#address-cells = <1>;
					#size-cells = <1>;
					reg-names = "queue-group0";
					reg = <0x80000 0x1000>;
					fsl,rx-bit-map = <0xFF>;
					fsl,tx-bit-map = <0xFF>;
					interrupts = <0 184 0x04>,
						     <0 183 0x04>,
						     <0 185 0x04>;
				};
			};

			enet1: ethernet@0xa1000 {
				#address-cells = <1>;
				#size-cells = <1>;
				device_type = "network";
				model = "eTSEC";
				compatible = "fsl,etsec2";
				fsl,num_rx_queues = <0x08>;
				fsl,num_tx_queues = <0x08>;
				fsl,errata = <0x00000004>;
				local-mac-address = [ 00 00 ab cd 23 ef ];
				phy-handle = <&phy2>;
				tbi-handle = <&tbi1>;
				phy-connection-type = "sgmii";
				reg = <0xa1000 0x1000>;
				ranges;
				status = "okay";

				queue-group@0 {
					#address-cells = <1>;
					#size-cells = <1>;
					reg-names = "queue-group0";
					reg = <0xa1000 0x1000>;
					fsl,rx-bit-map = <0xFF>;
					fsl,tx-bit-map = <0xFF>;
					interrupts = <0 191 0x04>,
						     <0 190 0x04>,
						     <0 192 0x04>;
				};
			};

			mdio@084000 {
				#address-cells = <1>;
				#size-cells = <0>;
				compatible = "fsl,etsec2-mdio";
				reg = <0x84000 0x4000>;
				status = "okay";

				phy0: vitesse-phy@0 {
					reg = <0>;
					device_type = "ethernet-phy";
				};

				phy2: vitesse-phy@2 {
					reg = <2>;
					device_type = "ethernet-phy";
				};

				tbi0: tbi-phy@10 {
					device_type = "tbi-phy";
					reg = <0x10>;
				};

				tbi1: tbi-phy@11 {
					device_type = "tbi-phy";
					reg = <0x11>;
				};
			};

			vspa@0x000d4000 {
				compatible = "fsl,vspa";
				reg = <0x000d4000 0x800>;
				dbgregstart = <0x20025000>;
				dbgreglen = <0x1000>;
				vspadev-id  = <11>;
				interrupts = <0 213 0x4>;
				status = "okay";
			};
			vspa@0x000d8000 {
				compatible = "fsl,vspa";
				reg = <0x000d8000 0x800>;
				dbgregstart = <0x20024000>;
				dbgreglen = <0x1000>;
				vspadev-id  = <10>;
				interrupts = <0 214 0x4>;
				status = "okay";
			};
			vspa@0x000DC000 {
				compatible = "fsl,vspa";
				reg = <0x000DC000 0x800>;
				dbgregstart = <0x20023000>;
				dbgreglen = <0x1000>;
				vspadev-id  = <9>;
				interrupts = <0 215 0x4>;
				status = "okay";
			};
			vspa@0x000e0000 {
				compatible = "fsl,vspa";
				reg = <0x000e0000 0x800>;
				dbgregstart = <0x20022000>;
				dbgreglen = <0x1000>;
				vspadev-id  = <8>;
				interrupts = <0 216 0x4>;
				status = "okay";
			};
			vspa@0x000e4000 {
				compatible = "fsl,vspa";
				reg = <0x000e4000 0x800>;
				dbgregstart = <0x20028000>;
				dbgreglen = <0x1000>;
				vspadev-id  = <7>;
				interrupts = <0 217 0x4>;
				status = "okay";
			};
			vspa@0x000e8000 {
				compatible = "fsl,vspa";
				reg = <0x000e8000 0x800>;
				dbgregstart = <0x20027000>;
				dbgreglen = <0x1000>;
				vspadev-id  = <6>;
				interrupts = <0 218 0x4>;
				status = "okay";
			};
			vspa@0x000EC000 {
				compatible = "fsl,vspa";
				reg = <0x000EC000 0x800>;
				dbgregstart = <0x20026000>;
				dbgreglen = <0x1000>;
				vspadev-id  = <5>;
				interrupts = <0 219 0x4>;
				status = "okay";
			};
			vspa@0x000f0000 {
				compatible = "fsl,vspa";
				reg = <0x000f0000 0x800>;
				dbgregstart = <0x20021000>;
				dbgreglen = <0x1000>;
				vspadev-id  = <4>;
				interrupts = <0 220 0x4>;
				status = "okay";
			};
			vspa@0x000f4000 {
				compatible = "fsl,vspa";
				reg = <0x000f4000 0x800>;
				dbgregstart = <0x20020000>;
				dbgreglen = <0x1000>;
				vspadev-id  = <3>;
				interrupts = <0 221 0x4>;
				status = "okay";
			};
			vspa@0x000f8000 {
				compatible = "fsl,vspa";
				reg = <0x000f8000 0x800>;
				dbgregstart = <0x2001F000>;
				dbgreglen = <0x1000>;
				vspadev-id  = <2>;
				interrupts = <0 222 0x4>;
				status = "okay";
			};
			vspa@0x000FC000 {
				compatible = "fsl,vspa";
				reg = <0x000FC000 0x800>;
				dbgregstart = <0x2001E000>;
				dbgreglen = <0x1000>;
				vspadev-id  = <1>;
				interrupts = <0 223 0x4>;
				status = "okay";
			};


			tbgen@0x94000 {
				#address-cells = <1>;
				#size-cells = <1>;
				compatible = "fsl,d4400-tbgen";
				reg = <0x00094000 0x8000>;
				interrupts = <0 176 0x4>;
			};
			gpc@0x98000 {
				#address-cells = <1>;
				#size-cells = <1>;
				compatible = "fsl,d4400-gpc";
				reg = <0x00098000 0x4000>;
				interrupts = <0 180 0x4>;
			};
		};

                weim-bus@30000000 {
                        compatible = "simple-bus";
                        #address-cells = <1>;
                        #size-cells = <1>;
                        reg = <0x30000000 0x20000000>;
                        ranges = <0x0 0x30000000 0x20000000>;
                };
        };
};

